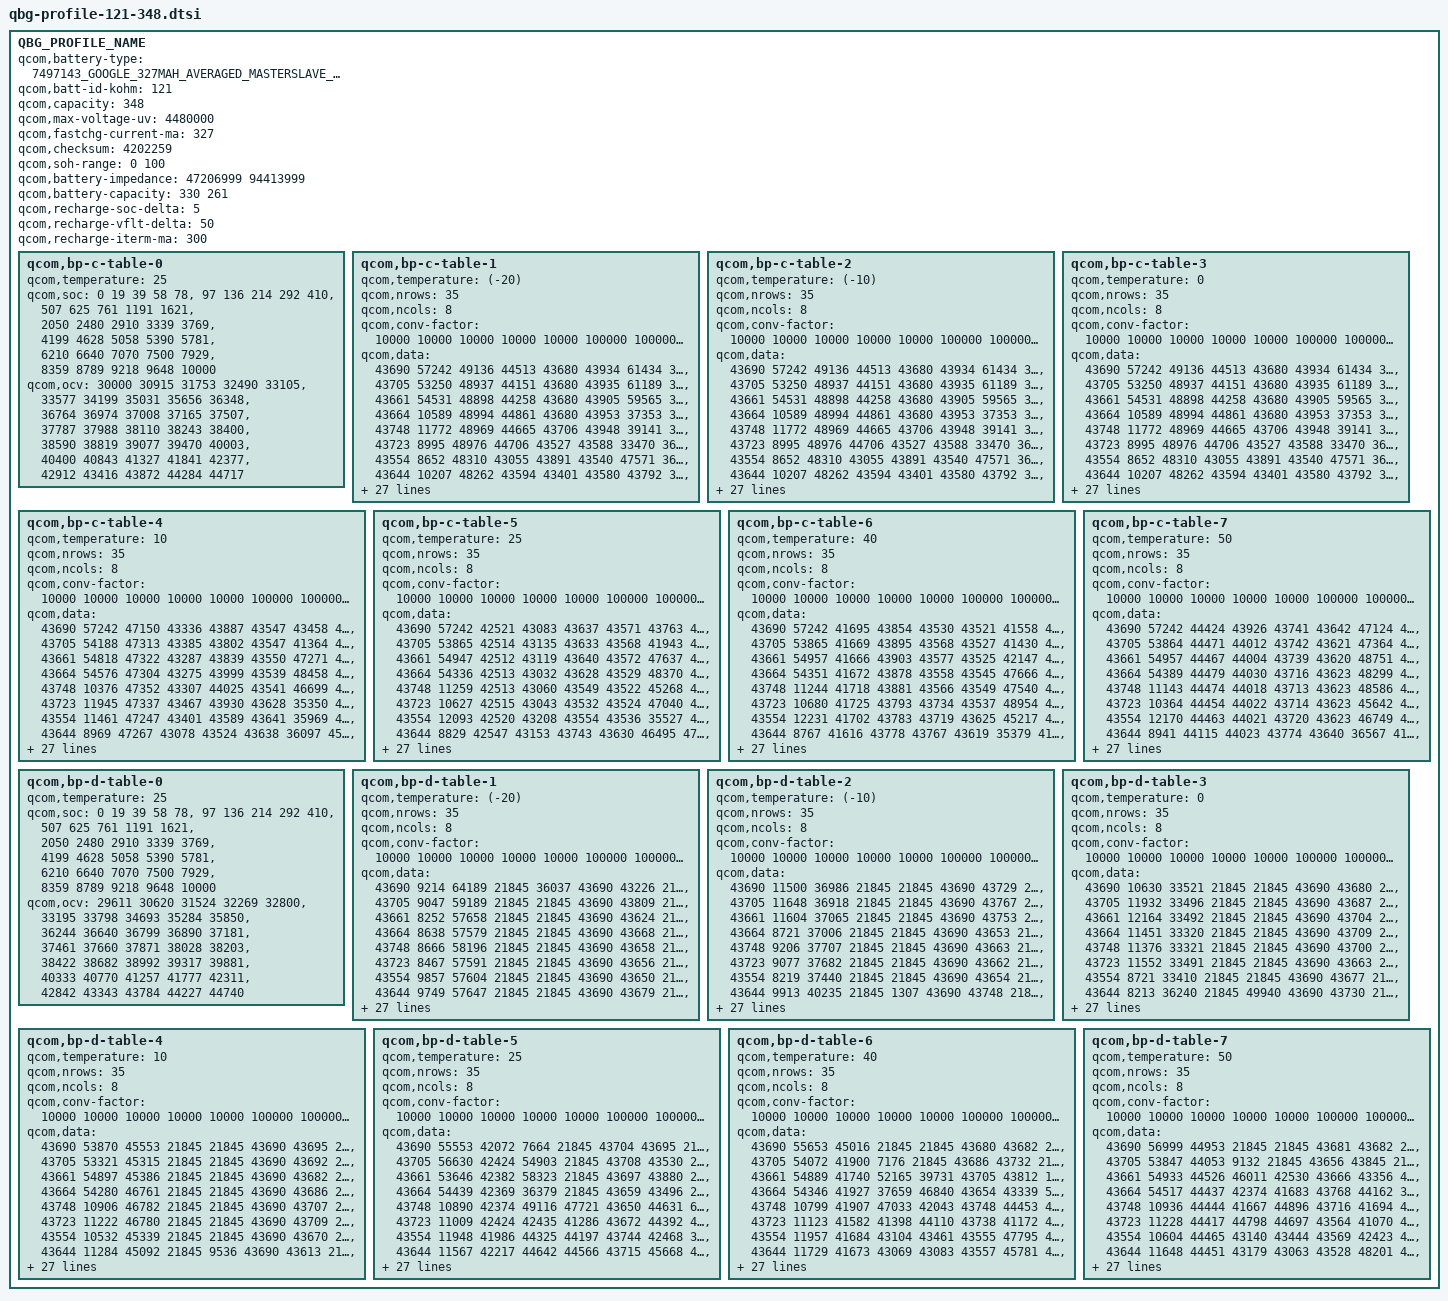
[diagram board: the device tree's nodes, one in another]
/*QBG Profiling Rev. 2.8*/

QBG_PROFILE_NAME {
	qcom,battery-type = "7497143_GOOGLE_327MAH_AVERAGED_MASTERSLAVE_DEC2ND2024";
	qcom,batt-id-kohm = <121>;
	qcom,capacity = <348>;
	qcom,max-voltage-uv = <4480000>;
	qcom,fastchg-current-ma = <327>;
	qcom,checksum = <4202259>; /*@5, 0.005V, 4% */
	qcom,soh-range = <0 100>;
	qcom,battery-impedance = <47206999 94413999>; /*Nominal_Impedance in 10nohm @ SOC 50% 25C* 0:fresh cell, 1: aged cell*/
	qcom,battery-capacity = <330 261>; /*Nominal_Capacity in mAh. 0: fresh cell, 1:aged cell*/
	qcom,recharge-soc-delta =<5>; /*SOC delta (in percent) dropped from EOC SOC to enable recharge*/
	qcom,recharge-vflt-delta =<50>; /*vfloat delta (in mV) dropped from regular vfloat in recharge*/
	qcom,recharge-iterm-ma = <300>; /*termination current (in mA) in recharge*/

	qcom,bp-c-table-0 {
		qcom,temperature = <25>;
		qcom,soc = <    0    19    39    58    78>,
			<   97   136   214   292   410>,
			<  507   625   761  1191  1621>,
			< 2050  2480  2910  3339  3769>,
			< 4199  4628  5058  5390  5781>,
			< 6210  6640  7070  7500  7929>,
			< 8359  8789  9218  9648 10000>;
		qcom,ocv = <30000 30915 31753 32490 33105>,
			<33577 34199 35031 35656 36348>,
			<36764 36974 37008 37165 37507>,
			<37787 37988 38110 38243 38400>,
			<38590 38819 39077 39470 40003>,
			<40400 40843 41327 41841 42377>,
			<42912 43416 43872 44284 44717>;
	};
	qcom,bp-c-table-1 {
		qcom,temperature = <(-20)>;
		qcom,nrows = <35>;
		qcom,ncols = <8>;
		qcom,conv-factor = <10000 10000 10000 10000 10000 100000 100000 10000>;
		qcom,data = <43690 57242 49136 44513 43680 43934 61434 36625>,
			<43705 53250 48937 44151 43680 43935 61189 36669>,
			<43661 54531 48898 44258 43680 43905 59565 36814>,
			<43664 10589 48994 44861 43680 43953 37353 36749>,
			<43748 11772 48969 44665 43706 43948 39141 36425>,
			<43723  8995 48976 44706 43527 43588 33470 36406>,
			<43554  8652 48310 43055 43891 43540 47571 36543>,
			<43644 10207 48262 43594 43401 43580 43792 35113>,
			<43918  9661 48988 43737 43479 43570 44022 35317>,
			<43824 15095 48331 43740 43327 43570 44025 35191>,
			<43857 14858 48313 43716 43456 43573 43977 35290>,
			<43227 14968 48279 43713 43295 43575 44013 35168>,
			<43091 15291 48323 43767 43389 43581 43927 36514>,
			<44557 14470 48566 43456 43257 43532 42342 36256>,
			<44287 14792 48492 41633 43784 43580 46786 33068>,
			<41640 16121 48483 41861 43137 43581 45780 34421>,
			<41754 15945 48491 41848 43122 43577 47459 34624>,
			<41460 16358 45730 41184 43502 43555 47269 34281>,
			<42913 16233 45817 41059 43319 43567 47906 39427>,
			<42003 15604 45597 41465 43329 43562 47727 39160>,
			<47821 15771 46050 41325 44682 43728 42476 39276>,
			<47294 12949 45897 42650 44768 43743 42905 40837>,
			<47464 13269 45300 42514 44588 43716 41383 40399>,
			<49060 12338 45122 42921 44667 43715 41898 37799>,
			<48191 12636 46726 42961 45053 43721 44543 37331>,
			<45800 14117 47049 42165 44173 43764 44220 37999>,
			<45914 13801 46934 41988 44525 43760 44990 59442>,
			<45364  2982 46122 42413 41567 43762 44682 60529>,
			<47078  2115 46356 42486 41468 43762 43475 59034>,
			<46163  3703 35446 42471 42108 43763 43110 63508>,
			<35341  3191 35667 42384 47390 43766 43235 61547>,
			<35071   613 35254 42261 45265 43764 43865 53109>,
			<36520    60 35140 47772 36008 43764 43807 56563>,
			<36634  1770 36353 42240 33896 43725 43969 10394>,
			<36282  1798 36681 41182 34276 43537 43584 10553>;
	};
	qcom,bp-c-table-2 {
		qcom,temperature = <(-10)>;
		qcom,nrows = <35>;
		qcom,ncols = <8>;
		qcom,conv-factor = <10000 10000 10000 10000 10000 100000 100000 10000>;
		qcom,data = <43690 57242 49136 44513 43680 43934 61434 36625>,
			<43705 53250 48937 44151 43680 43935 61189 36669>,
			<43661 54531 48898 44258 43680 43905 59565 36814>,
			<43664 10589 48994 44861 43680 43953 37353 36749>,
			<43748 11772 48969 44665 43706 43948 39141 36425>,
			<43723  8995 48976 44706 43527 43588 33470 36406>,
			<43554  8652 48310 43055 43891 43540 47571 36543>,
			<43644 10207 48262 43594 43401 43580 43792 35113>,
			<43918  9661 48988 43737 43479 43570 44022 35317>,
			<43824 15095 48331 43740 43327 43570 44025 35191>,
			<43857 14858 48313 43716 43456 43573 43977 35290>,
			<43227 14968 48279 43713 43295 43575 44013 35168>,
			<43091 15291 48323 43767 43389 43581 43927 36514>,
			<44557 14470 48566 43456 43257 43532 42342 36256>,
			<44287 14792 48492 41633 43784 43580 46786 33068>,
			<41640 16121 48483 41861 43137 43581 45780 34421>,
			<41754 15945 48491 41848 43122 43577 47459 34624>,
			<41460 16358 45730 41184 43502 43555 47269 34281>,
			<42913 16233 45817 41059 43319 43567 47906 39427>,
			<42003 15604 45597 41465 43329 43562 47727 39160>,
			<47821 15771 46050 41325 44682 43728 42476 39276>,
			<47294 12949 45897 42650 44768 43743 42905 40837>,
			<47464 13269 45300 42514 44588 43716 41383 40399>,
			<49060 12338 45122 42921 44667 43715 41898 37799>,
			<48191 12636 46726 42961 45053 43721 44543 37331>,
			<45800 14117 47049 42165 44173 43764 44220 37999>,
			<45914 13801 46934 41988 44525 43760 44990 59442>,
			<45364  2982 46122 42413 41567 43762 44682 60529>,
			<47078  2115 46356 42486 41468 43762 43475 59034>,
			<46163  3703 35446 42471 42108 43763 43110 63508>,
			<35341  3191 35667 42384 47390 43766 43235 61547>,
			<35071   613 35254 42261 45265 43764 43865 53109>,
			<36520    60 35140 47772 36008 43764 43807 56563>,
			<36634  1770 36353 42240 33896 43725 43969 10394>,
			<36282  1798 36681 41182 34276 43537 43584 10553>;
	};
	qcom,bp-c-table-3 {
		qcom,temperature = <0>;
		qcom,nrows = <35>;
		qcom,ncols = <8>;
		qcom,conv-factor = <10000 10000 10000 10000 10000 100000 100000 10000>;
		qcom,data = <43690 57242 49136 44513 43680 43934 61434 36625>,
			<43705 53250 48937 44151 43680 43935 61189 36669>,
			<43661 54531 48898 44258 43680 43905 59565 36814>,
			<43664 10589 48994 44861 43680 43953 37353 36749>,
			<43748 11772 48969 44665 43706 43948 39141 36425>,
			<43723  8995 48976 44706 43527 43588 33470 36406>,
			<43554  8652 48310 43055 43891 43540 47571 36543>,
			<43644 10207 48262 43594 43401 43580 43792 35113>,
			<43918  9661 48988 43737 43479 43570 44022 35317>,
			<43824 15095 48331 43740 43327 43570 44025 35191>,
			<43857 14858 48313 43716 43456 43573 43977 35290>,
			<43227 14968 48279 43713 43295 43575 44013 35168>,
			<43091 15291 48323 43767 43389 43581 43927 36514>,
			<44557 14470 48566 43456 43257 43532 42342 36256>,
			<44287 14792 48492 41633 43784 43580 46786 33068>,
			<41640 16121 48483 41861 43137 43581 45780 34421>,
			<41754 15945 48491 41848 43122 43577 47459 34624>,
			<41460 16358 45730 41184 43502 43555 47269 34281>,
			<42913 16233 45817 41059 43319 43567 47906 39427>,
			<42003 15604 45597 41465 43329 43562 47727 39160>,
			<47821 15771 46050 41325 44682 43728 42476 39276>,
			<47294 12949 45897 42650 44768 43743 42905 40837>,
			<47464 13269 45300 42514 44588 43716 41383 40399>,
			<49060 12338 45122 42921 44667 43715 41898 37799>,
			<48191 12636 46726 42961 45053 43721 44543 37331>,
			<45800 14117 47049 42165 44173 43764 44220 37999>,
			<45914 13801 46934 41988 44525 43760 44990 59442>,
			<45364  2982 46122 42413 41567 43762 44682 60529>,
			<47078  2115 46356 42486 41468 43762 43475 59034>,
			<46163  3703 35446 42471 42108 43763 43110 63508>,
			<35341  3191 35667 42384 47390 43766 43235 61547>,
			<35071   613 35254 42261 45265 43764 43865 53109>,
			<36520    60 35140 47772 36008 43764 43807 56563>,
			<36634  1770 36353 42240 33896 43725 43969 10394>,
			<36282  1798 36681 41182 34276 43537 43584 10553>;
	};
	qcom,bp-c-table-4 {
		qcom,temperature = <10>;
		qcom,nrows = <35>;
		qcom,ncols = <8>;
		qcom,conv-factor = <10000 10000 10000 10000 10000 100000 100000 10000>;
		qcom,data = <43690 57242 47150 43336 43887 43547 43458 46870>,
			<43705 54188 47313 43385 43802 43547 41364 47064>,
			<43661 54818 47322 43287 43839 43550 47271 47028>,
			<43664 54576 47304 43275 43999 43539 48458 46696>,
			<43748 10376 47352 43307 44025 43541 46699 46798>,
			<43723 11945 47337 43467 43930 43628 35350 46767>,
			<43554 11461 47247 43401 43589 43641 35969 45554>,
			<43644  8969 47267 43078 43524 43638 36097 45117>,
			<43918  9889 47272 43123 43531 43632 46687 45295>,
			<43824  9239 47268 43594 43256 43644 43889 45832>,
			<43857 15038 47960 43522 43215 43914 43839 46059>,
			<43227 14884 47976 43525 43214 43913 43836 46008>,
			<43091 14955 47893 43559 43009 43957 43974 45961>,
			<44557 15136 47982 43340 43630 43541 35498 45088>,
			<44287 14403 48077 44983 43917 43573 46618 45355>,
			<41640 14682 48041 44809 44021 43568 47087 45363>,
			<41754 15927 47677 44203 43813 43568 45211 45353>,
			<41460 16303 47816 44266 43801 43572 45261 45350>,
			<42913 16337 47770 44277 43897 43530 45244 45327>,
			<42003 15529 47759 44080 43846 43534 46189 45401>,
			<47821 15382 47855 44121 43176 43528 36461 46650>,
			<47294 15718 47651 44526 43870 43572 36713 47026>,
			<47464 13298 47712 44437 43865 43582 45119 47047>,
			<49060 12293 48033 44432 43175 43555 42166 46963>,
			<48191 13957 47913 44480 43063 43733 41575 46472>,
			<45800 14207 47941 44362 43421 43743 44144 35441>,
			<45914 13630 47143 41683 43363 43719 44921 34920>,
			<45364  3035 47548 41918 44579 43712 44627 36782>,
			<47078  2511 47430 41803 44838 43714 44756 36178>,
			<46163  4058 48679 41168 44448 43715 43330 33182>,
			<35341  3374 49037 41039 41927 43712 43396 34287>,
			<35071   983 49011 41462 42898 43713 43023 40876>,
			<36520   401 48350 41225 48862 43713 43237 38126>,
			<36634  1961 48552 44453 47140 43615 43810 37718>,
			<36282  1271 45729 45049 48203 43762 43963 38095>;
	};
	qcom,bp-c-table-5 {
		qcom,temperature = <25>;
		qcom,nrows = <35>;
		qcom,ncols = <8>;
		qcom,conv-factor = <10000 10000 10000 10000 10000 100000 100000 10000>;
		qcom,data = <43690 57242 42521 43083 43637 43571 43763 47140>,
			<43705 53865 42514 43135 43633 43568 41943 47308>,
			<43661 54947 42512 43119 43640 43572 47637 47263>,
			<43664 54336 42513 43032 43628 43529 48370 47957>,
			<43748 11259 42513 43060 43549 43522 45268 47980>,
			<43723 10627 42515 43043 43532 43524 47040 47910>,
			<43554 12093 42520 43208 43554 43536 35527 48011>,
			<43644  8829 42547 43153 43743 43630 46495 47642>,
			<43918  8674 42718 43140 43734 43628 48771 47656>,
			<43824 10070 42736 43179 43561 43640 47652 47746>,
			<43857  9526 42747 43179 43741 43643 47361 47786>,
			<43227 15044 42653 43947 44022 43944 44393 42349>,
			<43091 14906 42632 43183 43765 43640 46044 42270>,
			<44557 15239 41303 43087 43627 43534 48586 47706>,
			<44287 14377 41239 43305 43962 43582 48215 47882>,
			<41640 14641 41248 43373 43934 43582 48152 47968>,
			<41754 16078 41467 43358 43932 43577 48273 47969>,
			<41460 15988 41369 44714 44025 43577 47468 47992>,
			<42913 16329 41386 43345 43821 43576 42396 47999>,
			<42003 15530 41029 43346 43805 43576 42810 47966>,
			<47821 15380 41075 44731 43894 43579 42487 47240>,
			<47294 15625 41071 44777 43848 43576 48741 47341>,
			<47464 12815 40964 44554 43878 43568 33937 47324>,
			<49060 12420 40975 44770 43776 43582 46520 47955>,
			<48191 14057 41013 43389 43832 43552 44385 48072>,
			<45800 14202 41009 44694 43835 43555 41684 47975>,
			<45914 13601 40970 44552 43793 43561 44498 47326>,
			<45364  3013 40978 44952 43174 43735 44082 47576>,
			<47078  2523 41024 44824 43223 43730 44830 48694>,
			<46163  3875 41397 44170 43404 43740 44663 48989>,
			<35341  3338 41413 44045 44705 43742 44752 48403>,
			<35071   818 41244 44131 44835 43740 43336 45934>,
			<36520   458 41306 44060 41901 43732 43425 46888>,
			<36634  1622 42700 44984 44208 43732 44569 46040>,
			<36282  1031 42577 43493 42611 43740 43971 46568>;
	};
	qcom,bp-c-table-6 {
		qcom,temperature = <40>;
		qcom,nrows = <35>;
		qcom,ncols = <8>;
		qcom,conv-factor = <10000 10000 10000 10000 10000 100000 100000 10000>;
		qcom,data = <43690 57242 41695 43854 43530 43521 41558 41223>,
			<43705 53865 41669 43895 43568 43527 41430 41227>,
			<43661 54957 41666 43903 43577 43525 42147 41274>,
			<43664 54351 41672 43878 43558 43545 47666 41424>,
			<43748 11244 41718 43881 43566 43549 47540 41419>,
			<43723 10680 41725 43793 43734 43537 48954 41453>,
			<43554 12231 41702 43783 43719 43625 45217 41405>,
			<43644  8767 41616 43778 43767 43619 35379 41025>,
			<43918  8285 41604 43781 43773 43617 35172 41076>,
			<43824  9998 41611 43832 43775 43634 35797 40960>,
			<43857  9721 41648 43986 43763 43639 45521 40992>,
			<43227 15087 41659 44019 43751 43638 45241 41203>,
			<43091 15065 41632 44030 43769 43595 45630 41211>,
			<44557 14939 41641 43884 43641 43540 42506 41456>,
			<44287 14486 44378 43173 43936 43547 42768 41341>,
			<41640 14820 44407 43234 43963 43527 47315 42670>,
			<41754 16054 44386 43254 43605 43523 49018 42666>,
			<41460 15902 44319 43257 43604 43520 47771 41283>,
			<42913 16356 44341 43238 43934 43521 41022 42667>,
			<42003 16215 44346 43865 43875 43525 44901 42629>,
			<47821 15470 44328 43180 43868 43523 44097 42702>,
			<47294 15646 44499 43141 43857 43532 41911 42533>,
			<47464 12909 44506 43059 43885 43534 47427 42526>,
			<49060 12513 44481 43213 43971 43532 42862 42653>,
			<48191 13979 44492 43164 43933 43532 44053 41324>,
			<45800 14178 44489 43254 44008 43530 44235 41300>,
			<45914 13613 44489 43053 43980 43571 44845 42736>,
			<45364  3012 44492 43118 43812 43579 44964 42592>,
			<47078  2526 44482 43407 43880 43558 44547 42944>,
			<46163  3885 44506 43284 43194 43560 44665 42185>,
			<35341  3338 44329 43339 43035 43562 44725 42478>,
			<35071   826 44343 44794 43502 43565 44581 47869>,
			<36520   485 44306 44786 44646 43582 44726 47269>,
			<36634  1627 44354 43086 43082 43571 44822 41989>,
			<36282  1131 41668 43214 41429 43534 43838 48428>;
	};
	qcom,bp-c-table-7 {
		qcom,temperature = <50>;
		qcom,nrows = <35>;
		qcom,ncols = <8>;
		qcom,conv-factor = <10000 10000 10000 10000 10000 100000 100000 10000>;
		qcom,data = <43690 57242 44424 43926 43741 43642 47124 41925>,
			<43705 53864 44471 44012 43742 43621 47364 41945>,
			<43661 54957 44467 44004 43739 43620 48751 41948>,
			<43664 54389 44479 44030 43716 43623 48299 41948>,
			<43748 11143 44474 44018 43713 43623 48586 41951>,
			<43723 10364 44454 44022 43714 43623 45642 41944>,
			<43554 12170 44463 44021 43720 43623 46749 41923>,
			<43644  8941 44115 44023 43774 43640 36567 41955>,
			<43918  8194 44123 44027 43744 43638 34497 41871>,
			<43824 10232 44096 44031 43757 43595 33831 41908>,
			<43857  9647 44108 43904 43770 43615 35817 41562>,
			<43227 15015 44107 43608 43771 43601 48796 41502>,
			<43091 15082 44151 43614 43749 43607 48280 41498>,
			<44557 14878 44147 44008 43632 43595 41577 41780>,
			<44287 15189 44154 43985 43606 43640 41060 41811>,
			<41640 14752 44130 43784 43939 43623 42436 41091>,
			<41754 14711 44054 43789 43944 43616 47241 41102>,
			<41460 15935 44059 43786 43595 43628 42125 41822>,
			<42913 16272 44046 43803 43613 43631 41386 41151>,
			<42003 16216 44082 44008 43807 43645 44764 41208>,
			<47821 15381 44090 44008 43870 43623 44937 40997>,
			<47294 15646 44064 43969 43845 43628 44474 40990>,
			<47464 12914 44078 43886 43803 43624 42201 40982>,
			<49060 12528 44075 43836 44002 43628 41809 41110>,
			<48191 13958 44247 43995 43954 43619 44839 41840>,
			<45800 14188 44241 43832 43915 43541 44944 41121>,
			<45914 13603 44241 43797 44010 43550 44570 41167>,
			<45364  3033 44246 43845 43980 43520 44781 41060>,
			<47078  2525 44244 43250 43981 43572 44938 41448>,
			<46163  3876 44072 43031 43807 43579 44554 42671>,
			<35341  3380 44066 43416 43868 43559 45042 42602>,
			<35071   806 44091 43501 43048 43576 44629 42951>,
			<36520   481 44085 43415 43272 43568 44799 42024>,
			<36634  1607 44061 43180 43148 43538 44996 41321>,
			<36282  1124 44432 43820 41523 43595 43979 47344>;
	};
	qcom,bp-d-table-0 {
		qcom,temperature = <25>;
		qcom,soc = <    0    19    39    58    78>,
			<   97   136   214   292   410>,
			<  507   625   761  1191  1621>,
			< 2050  2480  2910  3339  3769>,
			< 4199  4628  5058  5390  5781>,
			< 6210  6640  7070  7500  7929>,
			< 8359  8789  9218  9648 10000>;
		qcom,ocv = <29611 30620 31524 32269 32800>,
			<33195 33798 34693 35284 35850>,
			<36244 36640 36799 36890 37181>,
			<37461 37660 37871 38028 38203>,
			<38422 38682 38992 39317 39881>,
			<40333 40770 41257 41777 42311>,
			<42842 43343 43784 44227 44740>;
	};
	qcom,bp-d-table-1 {
		qcom,temperature = <(-20)>;
		qcom,nrows = <35>;
		qcom,ncols = <8>;
		qcom,conv-factor = <10000 10000 10000 10000 10000 100000 100000 10000>;
		qcom,data = <43690  9214 64189 21845 36037 43690 43226 21845>,
			<43705  9047 59189 21845 21845 43690 43809 21845>,
			<43661  8252 57658 21845 21845 43690 43624 21845>,
			<43664  8638 57579 21845 21845 43690 43668 21845>,
			<43748  8666 58196 21845 21845 43690 43658 21845>,
			<43723  8467 57591 21845 21845 43690 43656 21845>,
			<43554  9857 57604 21845 21845 43690 43650 21845>,
			<43644  9749 57647 21845 21845 43690 43679 21845>,
			<43918 10114 58334 21845 27930 43690 43746 21845>,
			<43824 10003 60888 21845 56941 43690 43739 21845>,
			<43857  9396 60836 21845 63595 43690 43580 21845>,
			<43227  9272 60620 21845 37273 43690 43646 21845>,
			<43091  9644 61152 21845 34760 43690 43953 21845>,
			<44557 14991 38291  6070 46095 43691 43858 21845>,
			<44287 15272 38716 12515 36056 43691 43049 21845>,
			<41640 15164 36954 55313 34887 43691 43211 21845>,
			<41754 14495 37425 65334 46709 43688 43068 21845>,
			<41460 14462 39981 59540 48389 43688 43130 21845>,
			<42913 14813 40450 40841 47404 43689 43443 24408>,
			<42003 16053 39020 33270 47774 43694 43491 29603>,
			<47821 15973 39906 35152 42857 43694 43519 27465>,
			<47294 16180 39616 46502 41274 43692 43366  1454>,
			<47464 15397 34674 45506 41833 43693 44756 13698>,
			<49060 15831 34633 46008 41499 43683 44863 16270>,
			<48191 12926 34710 48213 41720 43681 44535  8524>,
			<45800 12324 32873 49050 41700 43685 41911 10743>,
			<45914 14039 33373 47613 41719 43696 41356 53528>,
			<45364 13403 36180 47931 44356 43729 48669 56758>,
			<47078  3000 33362 47888 41695 43735 47402 57324>,
			<46163  2542 33462 47158 41900 43728 47148 56452>,
			<35341  3881 36290 47416 41782 43742 47925 56727>,
			<35071  3354 36303 48848 41835 43713 42292 53936>,
			<36520   787 36294 48711 41960 43766 41306 56652>,
			<36634  1696 36230 48720 44078 43752 44455 57270>,
			<36282  1040 35963 48643 44928 43649 43226 55329>;
	};
	qcom,bp-d-table-2 {
		qcom,temperature = <(-10)>;
		qcom,nrows = <35>;
		qcom,ncols = <8>;
		qcom,conv-factor = <10000 10000 10000 10000 10000 100000 100000 10000>;
		qcom,data = <43690 11500 36986 21845 21845 43690 43729 21845>,
			<43705 11648 36918 21845 21845 43690 43767 21845>,
			<43661 11604 37065 21845 21845 43690 43753 21845>,
			<43664  8721 37006 21845 21845 43690 43653 21845>,
			<43748  9206 37707 21845 21845 43690 43663 21845>,
			<43723  9077 37682 21845 21845 43690 43662 21845>,
			<43554  8219 37440 21845 21845 43690 43654 21845>,
			<43644  9913 40235 21845  1307 43690 43748 21845>,
			<43918 10129 40135 21845 63208 43690 43573 21845>,
			<43824  9458 40840 21845 34363 43690 43986 21845>,
			<43857  9290 39156 21845 46609 43690 43189 21845>,
			<43227  9710 34071  9796 47563 43691 43225 21845>,
			<43091  9502 34251 63674 42845 43691 43405 21845>,
			<44557 14945 33421 46506 44353 43689 44929  1846>,
			<44287 15144 35894 46398 42502 43694 44762  2169>,
			<41640 14512 36545 45687 40981 43693 44665 11699>,
			<41754 14388 35212 47359 44370 43653 44828 55764>,
			<41460 14773 35605 42238 44815 43762 44128 52774>,
			<42913 14599 35459 42523 44703 43723 44312 62252>,
			<42003 16102 46365 41463 43456 43715 41614 63794>,
			<47821 16311 46336 40980 43450 43739 41778 64483>,
			<47294 15402 46341 41424 43402 43729 45919 64411>,
			<47464 15703 35509 41261 44709 43733 45715 64454>,
			<49060 13186 46405 41227 44556 43560 49091 64311>,
			<48191 12298 46359 41281 44954 43566 47186 64329>,
			<45800 14021 46445 42537 44910 43564 47992 63682>,
			<45914 13519 35493 42987 44232 43560 47660 63922>,
			<45364  2761 35515 42839 44138 43729 42014 63936>,
			<47078  2088 35344 42061 44450 43742 42204 65070>,
			<46163  3584 35481 42258 44492 43719 42836 65485>,
			<35341  3181 46385 47822 44390 43725 42895 64732>,
			<35071   543 46380 47682 44411 43722 41250 65017>,
			<36520   197 46380 48032 44418 43772 41791 64994>,
			<36634  1736 46540 47721 44549 43746 41634 65521>,
			<36282  1040 46560 42331 43452 43664 44462 63992>;
	};
	qcom,bp-d-table-3 {
		qcom,temperature = <0>;
		qcom,nrows = <35>;
		qcom,ncols = <8>;
		qcom,conv-factor = <10000 10000 10000 10000 10000 100000 100000 10000>;
		qcom,data = <43690 10630 33521 21845 21845 43690 43680 21845>,
			<43705 11932 33496 21845 21845 43690 43687 21845>,
			<43661 12164 33492 21845 21845 43690 43704 21845>,
			<43664 11451 33320 21845 21845 43690 43709 21845>,
			<43748 11376 33321 21845 21845 43690 43700 21845>,
			<43723 11552 33491 21845 21845 43690 43663 21845>,
			<43554  8721 33410 21845 21845 43690 43677 21845>,
			<43644  8213 36240 21845 49940 43690 43730 21845>,
			<43918  9921 36702 21845 32992 43690 43607 21845>,
			<43824  9449 35110   956 47513 43690 43162 21845>,
			<43857  9634 34955 57659 42539 43691 43398 21845>,
			<43227  9682 35795 35118 44367 43688 44589  4130>,
			<43091  9583 46127 48720 45007 43689 44897  8798>,
			<44557 14872 45510 41957 43063 43704 41742 64118>,
			<44287 15314 45310 41133 43303 43655 44368 59177>,
			<41640 14521 45849 41884 43121 43721 41123 61232>,
			<41754 14346 45859 41686 43231 43715 41047 38179>,
			<41460 14747 45846 41641 43137 43717 42751 37177>,
			<42913 14658 46039 41644 43856 43731 49136 37678>,
			<42003 15998 45931 41654 43248 43733 45395 37383>,
			<47821 16207 45868 41654 43432 43562 45602 37599>,
			<47294 15787 45942 41611 43472 43561 47138 37554>,
			<47464 13031 45883 41717 43339 43564 42352 37540>,
			<49060 13274 45868 41489 44696 43564 42107 37506>,
			<48191 12356 45859 41966 44593 43566 42848 37435>,
			<45800 13846 46044 41801 44982 43735 42724 37812>,
			<45914 13316 45840 41006 44841 43740 41038 37639>,
			<45364  2664 45839 41465 44907 43738 40986 37108>,
			<47078  2166 46050 41333 44198 43714 41843 37301>,
			<46163  3676 46023 42729 44179 43721 41565 37220>,
			<35341  3488 46042 42508 44276 43764 41695 38432>,
			<35071   592 46063 42579 44283 43760 41708 38784>,
			<36520    26 45959 42922 44826 43772 41701 38798>,
			<36634  1576 45980 42694 43293 43771 41569 37176>,
			<36282  1050 46075 41241 43159 43751 41887 37727>;
	};
	qcom,bp-d-table-4 {
		qcom,temperature = <10>;
		qcom,nrows = <35>;
		qcom,ncols = <8>;
		qcom,conv-factor = <10000 10000 10000 10000 10000 100000 100000 10000>;
		qcom,data = <43690 53870 45553 21845 21845 43690 43695 21845>,
			<43705 53321 45315 21845 21845 43690 43692 21845>,
			<43661 54897 45386 21845 21845 43690 43682 21845>,
			<43664 54280 46761 21845 21845 43690 43686 21845>,
			<43748 10906 46782 21845 21845 43690 43707 21845>,
			<43723 11222 46780 21845 21845 43690 43709 21845>,
			<43554 10532 45339 21845 21845 43690 43670 21845>,
			<43644 11284 45092 21845  9536 43690 43613 21845>,
			<43918  9116 45838 26997 36592 43690 43026 21845>,
			<43824  8572 45603 34433 41809 43691 44951 25512>,
			<43857 10037 48399 47220 44843 43689 44245 10300>,
			<43227  9638 48980 41216 43483 43693 41594 62356>,
			<43091  9534 48935 44096 43238 43655 41060 60276>,
			<44557 15028 49105 44625 43974 43765 41398 33941>,
			<44287 15345 48675 44213 43897 43742 48210 33049>,
			<41640 14532 48784 44267 43009 43731 48865 33739>,
			<41754 14783 48812 44171 43107 43733 47603 35963>,
			<41460 14630 47381 44202 43208 43561 47323 36454>,
			<42913 16022 47381 44218 43206 43565 49001 36531>,
			<42003 16290 47379 44203 43022 43564 47228 35080>,
			<47821 16195 47361 44884 43106 43555 42039 35212>,
			<47294 15453 47421 44212 43080 43555 42618 34893>,
			<47464 12951 47398 44237 43451 43554 42663 35240>,
			<49060 13259 47416 44035 43495 43565 41255 35321>,
			<48191 12364 47376 44459 43266 43561 41039 35180>,
			<45800 13920 47398 44502 44729 43562 41174 36564>,
			<45914 13426 47608 41659 44784 43732 40996 36854>,
			<45364  2650 47597 41668 44548 43739 41789 36027>,
			<47078  2464 47590 41578 44570 43737 41548 35844>,
			<46163  3981 47604 41567 44598 43736 41672 36281>,
			<35341  3476 47601 41862 44759 43738 41675 36137>,
			<35071   923 47603 41966 44799 43717 41570 33441>,
			<36520    66 47577 41882 43349 43719 41856 33437>,
			<36634  1549 47370 41511 43446 43725 41966 36096>,
			<36282  1036 47456 41630 43251 43720 41903 35900>;
	};
	qcom,bp-d-table-5 {
		qcom,temperature = <25>;
		qcom,nrows = <35>;
		qcom,ncols = <8>;
		qcom,conv-factor = <10000 10000 10000 10000 10000 100000 100000 10000>;
		qcom,data = <43690 55553 42072  7664 21845 43704 43695 21845>,
			<43705 56630 42424 54903 21845 43708 43530 21845>,
			<43661 53646 42382 58323 21845 43697 43880 21845>,
			<43664 54439 42369 36379 21845 43659 43496 21845>,
			<43748 10890 42374 49116 47721 43650 44631 61416>,
			<43723 11009 42424 42435 41286 43672 44392 40150>,
			<43554 11948 41986 44325 44197 43744 42468 36457>,
			<43644 11567 42217 44642 44566 43715 45668 46891>,
			<43918  9086 42163 44789 44587 43741 46971 45521>,
			<43824  9888 42872 44699 43093 43735 46452 46056>,
			<43857 10046 42869 43331 43903 43734 45172 48514>,
			<43227  9610 42786 43382 43880 43735 42584 48341>,
			<43091  9493 42974 43285 43999 43563 42676 48937>,
			<44557 15024 42933 43093 43549 43558 47983 47199>,
			<44287 15255 42596 43392 44011 43553 42707 47494>,
			<41640 14591 42751 43304 43893 43567 42750 47407>,
			<41754 14774 42633 43298 43161 43555 42670 47579>,
			<41460 14661 41300 43361 43231 43582 47333 47381>,
			<42913 15910 41288 43313 43231 43576 42761 47604>,
			<42003 16273 41232 43305 43263 43576 41138 47183>,
			<47821 15548 41217 43266 43181 43582 41083 47109>,
			<47294 15792 41266 43290 43870 43576 41166 47150>,
			<47464 13050 41257 43292 43857 43578 41795 47150>,
			<49060 13119 41439 43348 43143 43582 42537 47171>,
			<48191 12643 41463 44966 43496 43525 35424 49062>,
			<45800 14119 41453 44634 43275 43580 47995 49051>,
			<45914 13800 41363 44570 43477 43565 41186 48761>,
			<45364  2947 41369 44560 43423 43555 41617 48691>,
			<47078  2459 41372 44608 43107 43558 41711 48837>,
			<46163  4077 41454 44637 43220 43555 41637 48868>,
			<35341  3568 41461 44631 43157 43565 41623 48791>,
			<35071   997 41429 44629 43195 43554 41843 48791>,
			<36520   418 41218 44662 43181 43555 40988 48790>,
			<36634  1641 41289 44768 43145 43555 44377 48804>,
			<36282  1134 42673 43341 43211 43555 43441 47424>;
	};
	qcom,bp-d-table-6 {
		qcom,temperature = <40>;
		qcom,nrows = <35>;
		qcom,ncols = <8>;
		qcom,conv-factor = <10000 10000 10000 10000 10000 100000 100000 10000>;
		qcom,data = <43690 55653 45016 21845 21845 43680 43682 21845>,
			<43705 54072 41900  7176 21845 43686 43732 21845>,
			<43661 54889 41740 52165 39731 43705 43812   168>,
			<43664 54346 41927 37659 46840 43654 43339 51688>,
			<43748 10799 41907 47033 42043 43748 44453 40865>,
			<43723 11123 41582 41398 44110 43738 41172 45486>,
			<43554 11957 41684 43104 43461 43555 47795 42358>,
			<43644 11729 41673 43069 43083 43557 45781 42050>,
			<43918  9043 41701 43050 43291 43582 45389 42461>,
			<43824  9858 41616 43207 43100 43569 35767 42029>,
			<43857 10030 41625 43230 43881 43575 35365 42983>,
			<43227  9640 41613 43052 43604 43575 48999 42554>,
			<43091  9576 41653 43023 43610 43569 42824 42549>,
			<44557 15010 41636 43803 43554 43525 47962 41401>,
			<44287 15280 44379 43176 43611 43525 42975 41246>,
			<41640 14476 44385 43147 43923 43550 42618 41299>,
			<41754 14774 44308 43140 43899 43544 42756 42529>,
			<41460 14685 44313 43199 43048 43536 41598 42942>,
			<42913 15920 44300 43236 43149 43537 41553 42575>,
			<42003 16370 44349 43213 43855 43540 41094 42502>,
			<47821 15515 44327 43261 43784 43538 41191 42749>,
			<47294 15745 44332 43248 44007 43544 42666 41301>,
			<47464 13047 44503 43251 44004 43527 42514 41303>,
			<49060 13056 44510 43208 43879 43523 42577 42704>,
			<48191 12666 44483 43117 43504 43532 47671 42202>,
			<45800 14327 44490 43228 43508 43528 44339 42126>,
			<45914 13706 44535 43061 43092 43528 44076 42823>,
			<45364  2986 44534 43424 43156 43523 44532 42805>,
			<47078  2128 44490 43411 43778 43532 41650 42979>,
			<46163  4001 44481 43412 44008 43581 41129 42923>,
			<35341  3509 44497 43404 43915 43579 41360 42604>,
			<35071   959 44320 43132 43912 43582 41344 42529>,
			<36520   124 44336 43018 43907 43572 41462 42741>,
			<36634  1597 44292 43058 43955 43533 42480 42750>,
			<36282  1216 44395 43037 43606 43546 47256 42719>;
	};
	qcom,bp-d-table-7 {
		qcom,temperature = <50>;
		qcom,nrows = <35>;
		qcom,ncols = <8>;
		qcom,conv-factor = <10000 10000 10000 10000 10000 100000 100000 10000>;
		qcom,data = <43690 56999 44953 21845 21845 43681 43682 21845>,
			<43705 53847 44053  9132 21845 43656 43845 21845>,
			<43661 54933 44526 46011 42530 43666 43356 40506>,
			<43664 54517 44437 42374 41683 43768 44162 35279>,
			<43748 10936 44444 41667 44896 43716 41694 48448>,
			<43723 11228 44417 44798 44697 43564 41070 48053>,
			<43554 10604 44465 43140 43444 43569 42423 43003>,
			<43644 11648 44451 43179 43063 43528 48201 42537>,
			<43918  8967 44115 43851 43090 43533 45315 42498>,
			<43824  9918 44098 43849 43497 43527 35333 42611>,
			<43857 10215 44106 43903 43795 43547 46392 41368>,
			<43227  9318 44144 43856 43592 43527 45196 41000>,
			<43091  9525 44157 43158 43548 43522 47892 41009>,
			<44557  9551 44129 43928 43740 43643 48679 41866>,
			<44287 14936 44048 43826 43537 43642 48108 41751>,
			<41640 15185 44045 43814 43962 43644 41333 41820>,
			<41754 14401 44085 43994 43815 43636 41192 41184>,
			<41460 14660 44087 43889 43178 43585 41945 41344>,
			<42913 15891 44089 43198 43863 43615 41378 41456>,
			<42003 16345 44064 43847 43894 43636 41911 41402>,
			<47821 15598 44078 43850 43984 43644 41887 41020>,
			<47294 15760 44245 43902 43960 43621 41322 41137>,
			<47464 12999 44240 43883 43962 43622 42606 41124>,
			<49060 13083 44255 43799 43822 43617 42741 41180>,
			<48191 12567 44231 43878 43401 43625 41904 42636>,
			<45800 14286 44227 43178 43086 43631 44087 42634>,
			<45914 13750 44227 43113 43883 43613 41974 41340>,
			<45364  2641 44227 43077 43927 43618 41015 41256>,
			<47078  2128 44231 43087 43584 43535 42863 41348>,
			<46163  4006 44251 43027 43539 43572 47916 41075>,
			<35341  3505 44253 43228 43546 43530 47306 40999>,
			<35071   954 44074 43162 43550 43526 47277 41190>,
			<36520   101 44064 43867 43617 43536 47791 41090>,
			<36634  1575 44082 43796 43944 43628 42645 41097>,
			<36282  1226 44044 43828 43929 43621 41493 41104>;
	};
};
